# nrf7140_bbpr register map
Vendor: Nordic Semiconductor; Series: nRF71; File version: 1
Registers are 32-bit, read-write, reset 0x0 unless marked. A register's access mark holds for its fields unless they carry their own. Offsets are from the block's base; [hi:lo] are bit positions; lines under a group give offsets from that group; {n}, {i} and the like mark numbered series; 'fields as' and 'values as' point back to an identical list.

## VPRCLIC — VPR CLIC registers
Base 0xF0000000
0x00 CLIC group — Unspecified
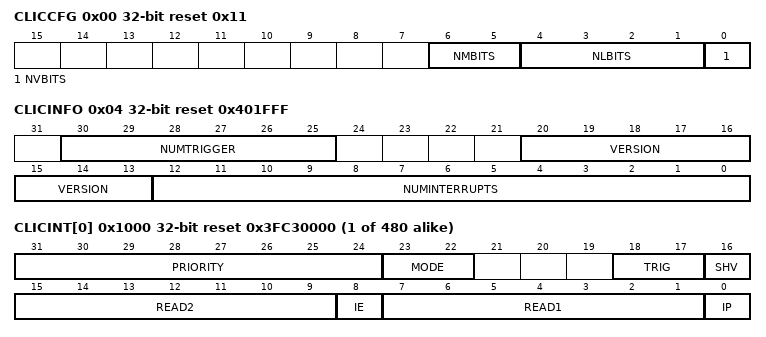
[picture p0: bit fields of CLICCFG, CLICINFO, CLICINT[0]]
  0x00 CLICCFG ro reset 0x11 — CLIC configuration.
    [6:5] NMBITS — Interrupt privilege mode.
      0=ModeM (All interrupts are M-mode only)
    [4:1] NLBITS — Interrupt level encoding.
      8=Eight (8 bits = interrupt levels encoded in eight bits)
    [0] NVBITS — Selective interrupt hardware vectoring.
      1=Implemented (Selective interrupt hardware vectoring is implemented)
  0x04 CLICINFO ro reset 0x401FFF — CLIC information.
    [30:25] NUMTRIGGER — Number of maximum interrupt triggers supported
    [20:13] VERSION
    [12:0] NUMINTERRUPTS — Maximum number of interrupts supported.
  {0x1000+4j} CLICINT[{j}] (j=0..479) reset 0x3FC30000 — Description collection: Interrupt control register for IRQ number [n].
    [31:24] PRIORITY — Interrupt priority level
      63=PRIOLEVEL0 (Priority level 0); 127=PRIOLEVEL1 (Priority level 1); 191=PRIOLEVEL2 (Priority level 2); 255=PRIOLEVEL3 (Priority level 3)
    [23:22] MODE ro — Privilege mode.
      3=MachineMode
    [18:17] TRIG ro — Trigger type and polarity for each interrupt input.
      1=EdgeTriggered (Interrupts are edge-triggered)
    [16] SHV ro — Selective Hardware Vectoring.
      1=Vectored (Hardware vectored)
    [15:9] READ2 ro — Read as 0, write ignored.
    [8] IE — Interrupt enable bit.
      0=Disabled (Interrupt disabled); 1=Enabled (Interrupt enabled)
    [7:1] READ1 ro — Read as 0, write ignored.
    [0] IP — Interrupt Pending bit.
      0=NotPending (Interrupt not pending); 1=Pending (Interrupt pending)

## GLOBAL_GFXPLLPM — AUXPM
Base 0x4900C000
0x20 TASKS_START wo — Request power up
  [0] TASKS_START
    1=Trigger task
0x24 TASKS_STOP wo — Stop requesting power up
  [0] TASKS_STOP
    1=Trigger task
0x110 EVENTS_SETTLED — LDO settled
  [0] EVENTS_SETTLED
    0=NotGenerated (Event not generated); 1=Generated (Event generated)
0x300 INTEN — Enable or disable interrupt
  [4] SETTLED — Enable or disable interrupt for event SETTLED
    0=Disabled; 1=Enabled
0x304 INTENSET — Enable interrupt
  [4] SETTLED — Write '1' to enable interrupt for event SETTLED
    on read: 0=Disabled (Read: Disabled); 1=Enabled (Read: Enabled) | on write: 1=Set (Enable)
0x308 INTENCLR — Disable interrupt
  [4] SETTLED — Write '1' to disable interrupt for event SETTLED
    on read: 0=Disabled (Read: Disabled); 1=Enabled (Read: Enabled) | on write: 1=Clear (Disable)
0x30C INTPEND ro — Pending interrupts
  [4] SETTLED — Read pending status of interrupt for event SETTLED
    on read: 0=NotPending (Read: Not pending); 1=Pending (Read: Pending)
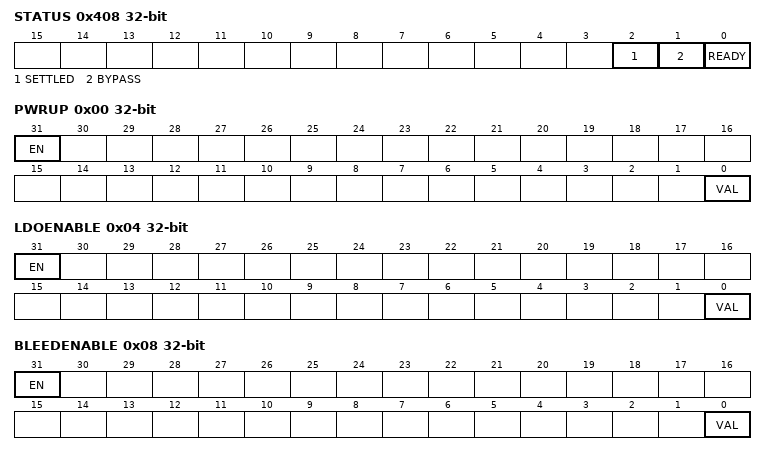
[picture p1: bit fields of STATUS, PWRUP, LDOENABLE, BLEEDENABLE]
0x408 STATUS ro — Status of AuxPm
  [2] SETTLED — LDO settled
    0=NotSettled (AuxPm not settled); 1=Settled (AuxPm settled)
  [1] BYPASS — Bypassing vref filter for startup boost
    0=NotBypass (VrefFilt not bypassed); 1=Bypass (VrefFilt bypassed)
  [0] READY — AuxPm powered up
    0=PowerDown (AuxPm powered down); 1=Powered (AuxPm powered up)
0x420 CONFIG group — Unspecified
  0x00 STARTUPTIME reset 0x18 — Time from pwrup to ready signal (0us-3us)
    [5:0] VAL — Timer value
      0=Min (0 us); 24=Default (1.5 us); 48=Max (3 us)
  0x04 SHUTDOWNTIME reset 0x18 — Time from shutdown until to ready signal is deasserted (0us-3us)
    fields as CONFIG.STARTUPTIME
  0x08 BYPASSTIME reset 0x70 — Time from ready until bypass vref turned off (7us-40us)
    [9:0] VAL — Timer value
      112=Min (7 us); 112=Default (7 us); 0x280=Max (40 us)
  0x0C SETLTIME reset 0x18 — Time from bypass turned off to settled (0us-3us)
    fields as CONFIG.STARTUPTIME
0x450 TRIM group — Unspecified
  0x00 VREFPM — Reference voltage trimming. Equals output voltage
    [2:0] VAL — Voltage trimming value.
      0=Val800mV (800 mV); 1=Val825mV (825 mV); 2=Val850mV (850 mV); 3=Val900mV (900 mV); 4=Val600mV (600 mV); 5=Val650mV (650 mV); 6=Val700mV (700 mV); 7=Val750mV (750 mV)
0x4F0 MIRROR — Enable LOCK for mirrored registers
  [0] LOCK — Lock for mirrored registers
    0=Disabled (Lock disabled); 1=Enabled (Lock enabled)
0x580 OVERRIDE group — Unspecified
  0x00 PWRUP — Override the pwrup to the analog module
    [31] EN — Enable the override
      0=Disabled (Override is disabled); 1=Enabled (Override is enabled)
    [0] VAL — Override value for the signal
  0x04 LDOENABLE — Override the LDO enable to the analog module
    fields as OVERRIDE.PWRUP
  0x08 BLEEDENABLE — Override the bleed enable to the analog module
    fields as OVERRIDE.PWRUP
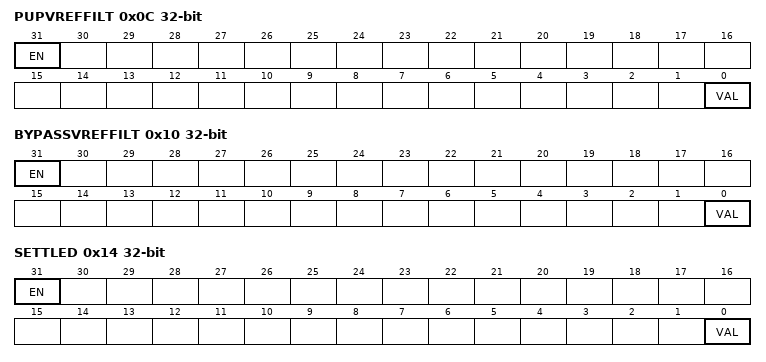
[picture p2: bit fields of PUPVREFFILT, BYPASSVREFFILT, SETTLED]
  0x0C PUPVREFFILT — Override the vref filter enable to the analog module
    fields as OVERRIDE.PWRUP
  0x10 BYPASSVREFFILT — Override the vref bypass to the analog module
    fields as OVERRIDE.PWRUP
  0x14 SETTLED — Override the SETTLED from the digital part
    fields as OVERRIDE.PWRUP
0x680 DFT group — Unspecified
  0x00 ATB0CONFIG — Analog Test Bus 0 (ATB0) configuration
    [31] EN
      0=Disabled (Analog test bus is disabled); 1=Enabled (Analog test bus is enabled)
  0x04 ATB1CONFIG — Analog Test Bus 1 (ATB1) configuration
    fields as DFT.ATB0CONFIG

## GLOBAL_CANPLLPM — AUXPM 0
Base 0x5F8C2000; alternate view of GLOBAL_CANPLL
Same registers: GLOBAL_AUDIOPLLPM 0x5F968000
Registers as GLOBAL_GFXPLLPM.

## Notices in the file
Copyright (c) 2010 - 2024, Nordic Semiconductor ASA
All rights reserved.
Redistribution and use in source and binary forms, with or without modification,
are permitted provided that the following conditions are met:
1. Redistributions of source code must retain the above copyright notice, this
list of conditions and the following disclaimer.
2. Redistributions in binary form, except as embedded into a Nordic
Semiconductor ASA integrated circuit in a product or a software update for
such product, must reproduce the above copyright notice, this list of
conditions and the following disclaimer in the documentation and/or other
materials provided with the distribution.
3. Neither the name of Nordic Semiconductor ASA nor the names of its
contributors may be used to endorse or promote products derived from this
software without specific prior written permission.
4. This software, with or without modification, must only be used with a
Nordic Semiconductor ASA integrated circuit.
5. Any software provided in binary form under this license must not be reverse
engineered, decompiled, modified and/or disassembled.
THIS SOFTWARE IS PROVIDED BY NORDIC SEMICONDUCTOR ASA "AS IS" AND ANY EXPRESS
OR IMPLIED WARRANTIES, INCLUDING, BUT NOT LIMITED TO, THE IMPLIED WARRANTIES
OF MERCHANTABILITY, NONINFRINGEMENT, AND FITNESS FOR A PARTICULAR PURPOSE ARE
DISCLAIMED. IN NO EVENT SHALL NORDIC SEMICONDUCTOR ASA OR CONTRIBUTORS BE
LIABLE FOR ANY DIRECT, INDIRECT, INCIDENTAL, SPECIAL, EXEMPLARY, OR
CONSEQUENTIAL DAMAGES (INCLUDING, BUT NOT LIMITED TO, PROCUREMENT OF SUBSTITUTE
GOODS OR SERVICES; LOSS OF USE, DATA, OR PROFITS; OR BUSINESS INTERRUPTION)
HOWEVER CAUSED AND ON ANY THEORY OF LIABILITY, WHETHER IN CONTRACT, STRICT
LIABILITY, OR TORT (INCLUDING NEGLIGENCE OR OTHERWISE) ARISING IN ANY WAY OUT
OF THE USE OF THIS SOFTWARE, EVEN IF ADVISED OF THE POSSIBILITY OF SUCH DAMAGE.
